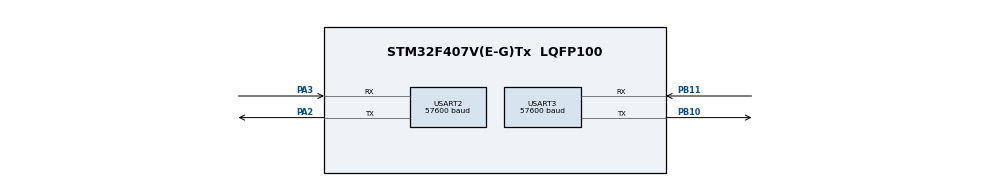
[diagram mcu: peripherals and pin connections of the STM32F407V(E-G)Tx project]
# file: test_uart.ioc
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Mcu.Family=STM32F4
Mcu.Name=STM32F407V(E-G)Tx
Mcu.Package=LQFP100
NVIC.PriorityGroup=NVIC_PRIORITYGROUP_4
NVIC.USART2_IRQn=true\:0\:0\:false\:false\:true\:true
NVIC.USART3_IRQn=true\:0\:0\:false\:false\:true\:true
PA2.Mode=Asynchronous
PA2.Signal=USART2_TX
PA3.Mode=Asynchronous
PA3.Signal=USART2_RX
PB10.Mode=Asynchronous
PB10.Signal=USART3_TX
PB11.Mode=Asynchronous
PB11.Signal=USART3_RX
PC14-OSC32_IN.Mode=LSE-External-Oscillator
PC14-OSC32_IN.Signal=RCC_OSC32_IN
PC15-OSC32_OUT.Mode=LSE-External-Oscillator
PC15-OSC32_OUT.Signal=RCC_OSC32_OUT
PH0-OSC_IN.Mode=HSE-External-Oscillator
PH0-OSC_IN.Signal=RCC_OSC_IN
PH1-OSC_OUT.Mode=HSE-External-Oscillator
PH1-OSC_OUT.Signal=RCC_OSC_OUT
ProjectManager.HeapSize=0x200
ProjectManager.StackSize=0x400
ProjectManager.TargetToolchain=SW4STM32
RCC.AHBFreq_Value=16000000
RCC.APB1Freq_Value=16000000
RCC.APB2Freq_Value=16000000
RCC.CortexFreq_Value=16000000
RCC.HSE_VALUE=25000000
RCC.HSI_VALUE=16000000
RCC.SYSCLKFreq_VALUE=16000000
RCC.VCOOutputFreq_Value=192000000
USART2.BaudRate=57600
USART2.VirtualMode=VM_ASYNC
USART3.BaudRate=57600
USART3.VirtualMode=VM_ASYNC
board=custom

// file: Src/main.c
/* USER CODE BEGIN Header */
/**
 ******************************************************************************
 * @file           : main.c
 * @brief          : Main program body
 ******************************************************************************
 ** This notice applies to any and all portions of this file
 * that are not between comment pairs USER CODE BEGIN and
 * USER CODE END. Other portions of this file, whether
 * inserted by the user or by software development tools
 * are owned by their respective copyright owners.
 *
 * COPYRIGHT(c) 2019 STMicroelectronics
 *
 * Redistribution and use in source and binary forms, with or without modification,
 * are permitted provided that the following conditions are met:
 *   1. Redistributions of source code must retain the above copyright notice,
 *      this list of conditions and the following disclaimer.
 *   2. Redistributions in binary form must reproduce the above copyright notice,
 *      this list of conditions and the following disclaimer in the documentation
 *      and/or other materials provided with the distribution.
 *   3. Neither the name of STMicroelectronics nor the names of its contributors
 *      may be used to endorse or promote products derived from this software
 *      without specific prior written permission.
 *
 * THIS SOFTWARE IS PROVIDED BY THE COPYRIGHT HOLDERS AND CONTRIBUTORS "AS IS"
 * AND ANY EXPRESS OR IMPLIED WARRANTIES, INCLUDING, BUT NOT LIMITED TO, THE
 * IMPLIED WARRANTIES OF MERCHANTABILITY AND FITNESS FOR A PARTICULAR PURPOSE ARE
 * DISCLAIMED. IN NO EVENT SHALL THE COPYRIGHT HOLDER OR CONTRIBUTORS BE LIABLE
 * FOR ANY DIRECT, INDIRECT, INCIDENTAL, SPECIAL, EXEMPLARY, OR CONSEQUENTIAL
 * DAMAGES (INCLUDING, BUT NOT LIMITED TO, PROCUREMENT OF SUBSTITUTE GOODS OR
 * SERVICES; LOSS OF USE, DATA, OR PROFITS; OR BUSINESS INTERRUPTION) HOWEVER
 * CAUSED AND ON ANY THEORY OF LIABILITY, WHETHER IN CONTRACT, STRICT LIABILITY,
 * OR TORT (INCLUDING NEGLIGENCE OR OTHERWISE) ARISING IN ANY WAY OUT OF THE USE
 * OF THIS SOFTWARE, EVEN IF ADVISED OF THE POSSIBILITY OF SUCH DAMAGE.
 *
 ******************************************************************************
 */
/* USER CODE END Header */

#include "main.h"
#include <stm32f4xx_hal.h>
#include "uart.h"
#include "init_uart.h"
#include <string.h>

int main(void)
{

	/* MCU Configuration--------------------------------------------------------*/

	/* Reset of all peripherals, Initializes the Flash interface and the Systick. */
	HAL_Init();

	/* Configure the system clock */
	SystemClock_Config();

	/* Initialize all configured peripherals */
	MX_GPIO_Init();
	MX_USART2_UART_Init();
	MX_USART3_UART_Init();

	/* Infinite loop */
	/* USER CODE BEGIN WHILE */
	HAL_UART_Transmit(&huart2,(uint8_t*)"\033c",5,10);

	init_lora(1);
	//HAL_UART_Receive_IT(&huart3,bufferdata1,sizeof(bufferdata1));
	envoie_lora(10,2,"aa");

	while (1)
	{

		/* USER CODE BEGIN 3 */
		init_lora(1);
		reception_lora(10);
	}
	/* USER CODE END 3 */
}

/* USER CODE BEGIN 4 */
/*void HAL_UART_RxCpltCallback(UART_HandleTypeDef *huart)
{

	if(huart==&huart3)
	{
		HAL_UART_Transmit(&huart2,bufferdata1,sizeof(bufferdata1),tx_timout);
	}
}*/

/* USER CODE END 4 */

void Error_Handler(void)
{
}

/************************ (C) COPYRIGHT STMicroelectronics *****END OF FILE****/
